# CH32H417 register map
Vendor: WCH Ltd.; File version: 1.3
Registers are 32-bit, read-write, reset 0x0 unless marked. A register's access mark holds for its fields unless they carry their own. Offsets are from the block's base; [hi:lo] are bit positions; {n}, {i} and the like mark numbered series; 'fields as' and 'values as' point back to an identical list.

## CAN1 — Controller area network
Base 0x40006400
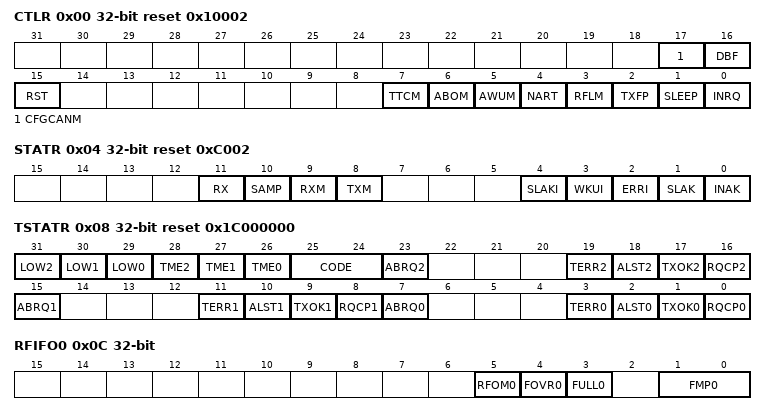
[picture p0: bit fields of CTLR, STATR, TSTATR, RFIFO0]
0x00 CTLR reset 0x10002 — CAN Master control register
  [17] CFGCANM — Configure CAN offline recovery time
  [16] DBF — Debug freeze
  [15] RST — Software master reset
  [7] TTCM — Time triggered communication mode
  [6] ABOM — Automatic bus-off management
  [5] AWUM — Automatic wakeup mode
  [4] NART — No automatic retransmission
  [3] RFLM — Receive FIFO locked mode
  [2] TXFP — Transmit FIFO priority
  [1] SLEEP — Sleep mode request bit
  [0] INRQ — Initialization request
0x04 STATR access per field reset 0xC002 — CAN master status register
  [11] RX ro — Rx signal
  [10] SAMP ro — Last sample point
  [9] RXM ro — Receive mode
  [8] TXM ro — Transmit mode
  [4] SLAKI rw — Sleep acknowledge interrupt
  [3] WKUI rw — Wakeup interrupt
  [2] ERRI rw — Error interrupt
  [1] SLAK ro — Sleep acknowledge
  [0] INAK ro — Initialization acknowledge
0x08 TSTATR access per field reset 0x1C000000 — CAN transmit status register
  [31] LOW2 ro — Lowest priority flag for mailbox2
  [30] LOW1 ro — Lowest priority flag for mailbox1
  [29] LOW0 ro — Lowest priority flag for mailbox0
  [28] TME2 ro — Transmit mailbox 2 empty
  [27] TME1 ro — Transmit mailbox 1 empty
  [26] TME0 ro — Transmit mailbox 0 empty
  [25:24] CODE ro — Mailbox code
  [23] ABRQ2 rw — Abort request for mailbox 2
  [19] TERR2 rw — Transmission error of mailbox 2
  [18] ALST2 rw — Arbitration lost for mailbox 2
  [17] TXOK2 rw — Transmission OK of mailbox 2
  [16] RQCP2 rw — Request completed mailbox2
  [15] ABRQ1 rw — Abort request for mailbox 1
  [11] TERR1 rw — Transmission error of mailbox1
  [10] ALST1 rw — Arbitration lost for mailbox1
  [9] TXOK1 rw — Transmission OK of mailbox1
  [8] RQCP1 rw — Request completed mailbox1
  [7] ABRQ0 rw — Abort request for mailbox0
  [3] TERR0 rw — Transmission error of mailbox0
  [2] ALST0 rw — Arbitration lost for mailbox0
  [1] TXOK0 rw — Transmission OK of mailbox0
  [0] RQCP0 rw — Request completed mailbox0
0x0C RFIFO0 access per field — CAN receive FIFO 0 register
  [5] RFOM0 rw — Release FIFO 0 output mailbox
  [4] FOVR0 rw — FIFO 0 overrun
  [3] FULL0 rw — FIFO 0 full
  [1:0] FMP0 ro — FIFO 0 message pending
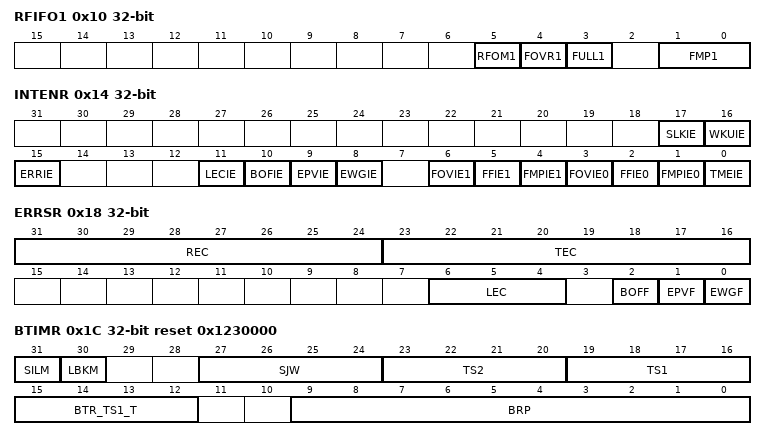
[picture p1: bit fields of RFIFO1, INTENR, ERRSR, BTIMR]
0x10 RFIFO1 access per field — CAN receive FIFO 1 register
  [5] RFOM1 rw — Release FIFO 1 output mailbox
  [4] FOVR1 rw — FIFO 1 overrun
  [3] FULL1 rw — FIFO 1 full
  [1:0] FMP1 ro — FIFO 1 message pending
0x14 INTENR — CAN interrupt enable register
  [17] SLKIE — Sleep interrupt enable
  [16] WKUIE — Wakeup interrupt enable
  [15] ERRIE — Error interrupt enable
  [11] LECIE — Last error code interrupt enable
  [10] BOFIE — Bus-off interrupt enable
  [9] EPVIE — Error passive interrupt enable
  [8] EWGIE — Error warning interrupt enable
  [6] FOVIE1 — FIFO overrun interrupt enable
  [5] FFIE1 — FIFO full interrupt enable
  [4] FMPIE1 — FIFO message pending interrupt enable
  [3] FOVIE0 — FIFO overrun interrupt enable
  [2] FFIE0 — FIFO full interrupt enable
  [1] FMPIE0 — FIFO message pending interrupt enable
  [0] TMEIE — Transmit mailbox empty interrupt enable
0x18 ERRSR access per field — CAN error status register
  [31:24] REC ro — Receive error counter
  [23:16] TEC ro — Least significant byte of the 9-bit transmit error counter
  [6:4] LEC rw — Last error code
  [2] BOFF ro — Bus-off flag
  [1] EPVF ro — Error passive flag
  [0] EWGF ro — Error warning flag
0x1C BTIMR reset 0x1230000 — CAN bit timing register
  [31] SILM — Silent mode (debug)
  [30] LBKM — Loop back mode (debug)
  [27:24] SJW — Resynchronization jump width
  [23:20] TS2 — Time segment 2
  [19:16] TS1 — Time segment 1
  [15:12] BTR_TS1_T — CLAS_LONG_TS1=0;TS1 is TS[3:0](4bit);CLAS_LONG_TS1=1,TS1 is TS[1:0]+BTR_TS1_T[15:12](6bit)
  [9:0] BRP — minimum time unit length setting value
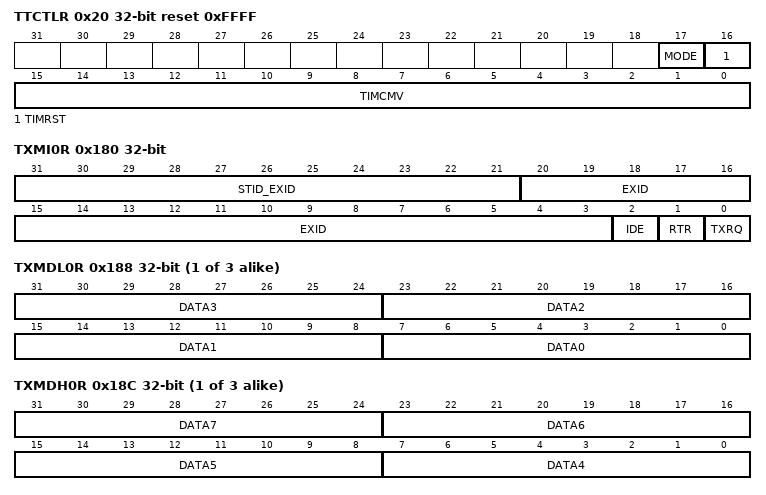
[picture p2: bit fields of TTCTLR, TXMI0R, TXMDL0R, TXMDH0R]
0x20 TTCTLR reset 0xFFFF — CAN time trigger control register
  [17] MODE — Time-triggered mode selection
  [16] TIMRST wo — Internal counter reset control
  [15:0] TIMCMV — Internal counter count end value
0x24 TTCNT — CAN Time Trigger Count Value Register
  [15:0] TIMCNT — time-triggered count value
0x28 TERR_CNT — CAN offline recovery error counter
  [8:0] TX_ERR_CNT — Offline recovery error count values
0x180 TXMI0R — CAN TX mailbox identifier register
  [31:21] STID_EXID — Standard identifier
  [20:3] EXID — extended identifier
  [2] IDE — Identifier extension
  [1] RTR — Remote transmission request
  [0] TXRQ — Transmit mailbox request
0x184 TXMDT0R — CAN mailbox data length control and time stamp register
  [31:16] TIME — Message time stamp
  [15:8] FMI ro — Filter match index
  [8] TGT — Transmit global time
  [3:0] DLC — Data length code
{0x188+0x10*i} TXMDL{i}R (i=0..2) — CAN mailbox data low register
  [8n+7:8n] DATA{n} (n=0..3) — Data byte {n}
{0x18C+0x10*i} TXMDH{i}R (i=0..2) — CAN mailbox data high register
  [8n-25:8n-32] DATA{n} (n=4..7) — Data byte {n}
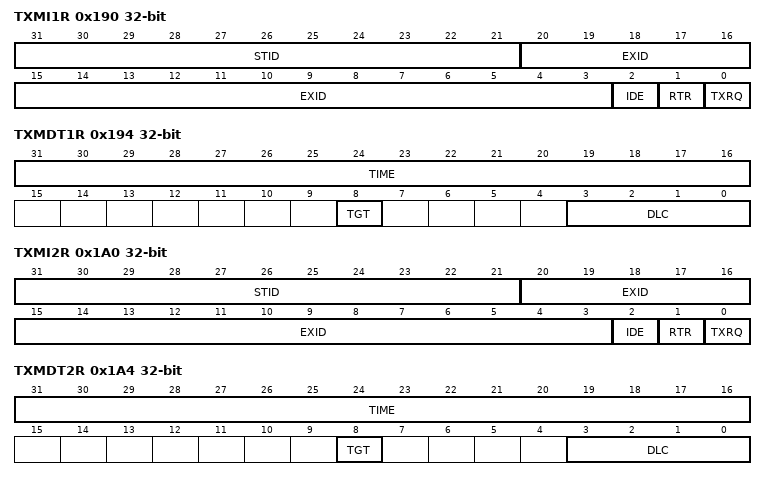
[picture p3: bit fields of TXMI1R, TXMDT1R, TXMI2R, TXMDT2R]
0x190 TXMI1R — CAN TX mailbox identifier register
  [31:21] STID — Standard identifier
  [20:3] EXID — extended identifier
  [2] IDE — Identifier extension
  [1] RTR — Remote transmission request
  [0] TXRQ — Transmit mailbox request
0x194 TXMDT1R — CAN mailbox data length control and time stamp register
  [31:16] TIME — Message time stamp
  [8] TGT — Transmit global time
  [3:0] DLC — Data length code
0x1A0 TXMI2R — CAN TX mailbox identifier register
  fields as TXMI1R
0x1A4 TXMDT2R — CAN mailbox data length control and time stamp register
  fields as TXMDT1R
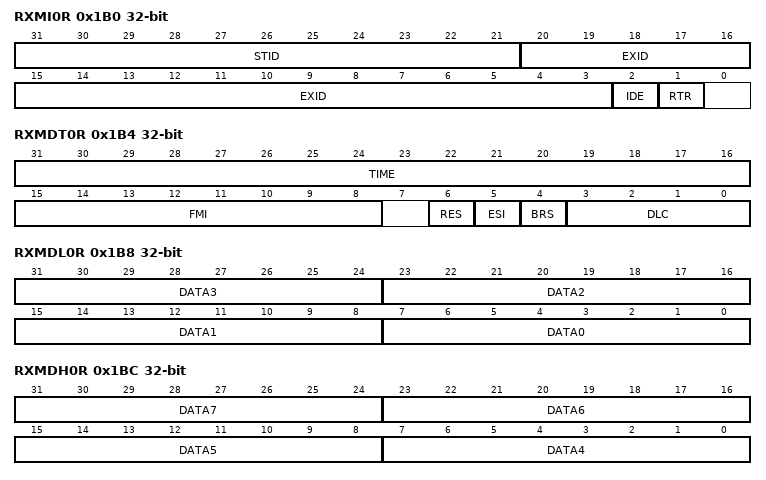
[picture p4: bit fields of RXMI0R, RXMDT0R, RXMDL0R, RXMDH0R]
0x1B0 RXMI0R ro — CAN receive FIFO mailbox identifier register
  [31:21] STID — Standard identifier
  [20:3] EXID — extended identifier
  [2] IDE — Identifier extension
  [1] RTR — Remote transmission request
0x1B4 RXMDT0R ro — CAN receive FIFO mailbox data length control and time stamp register
  [31:16] TIME — Message time stamp
  [15:8] FMI — Filter match index
  [6] RES — RES bit of the received frame
  [5] ESI — ESI bit of the received frame
  [4] BRS — BRS bit of the received frame
  [3:0] DLC — Data length code
0x1B8 RXMDL0R ro — CAN receive FIFO mailbox data low register
  [8n+7:8n] DATA{n} (n=0..3) — Data Byte {n}
0x1BC RXMDH0R ro — CAN receive FIFO mailbox data high register
  [8n-25:8n-32] DATA{n} (n=4..7)
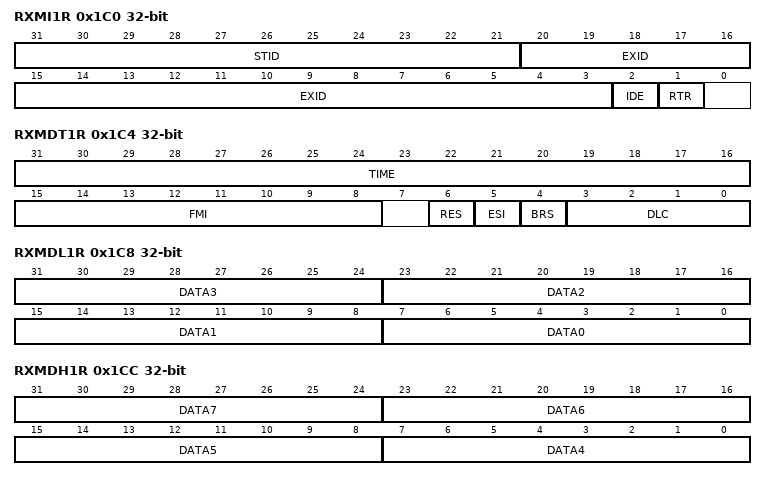
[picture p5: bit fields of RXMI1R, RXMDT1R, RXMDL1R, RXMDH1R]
0x1C0 RXMI1R ro — CAN receive FIFO mailbox identifier register
  fields as RXMI0R
0x1C4 RXMDT1R ro — CAN receive FIFO mailbox data length control and time stamp register
  fields as RXMDT0R
0x1C8 RXMDL1R ro — CAN receive FIFO mailbox data low register
  [8n+7:8n] DATA{n} (n=0..3) — Data Byte {n}
0x1CC RXMDH1R ro — CAN receive FIFO mailbox data high register
  [8n-25:8n-32] DATA{n} (n=4..7)
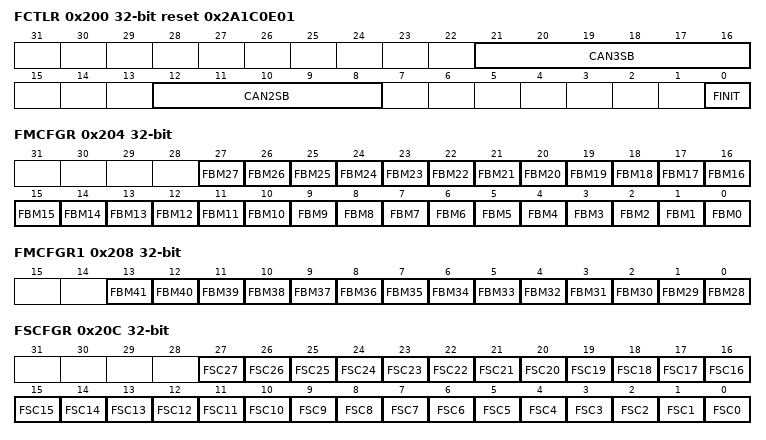
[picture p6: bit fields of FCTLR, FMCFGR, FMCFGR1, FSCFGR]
0x200 FCTLR reset 0x2A1C0E01 — CAN filter master register
  [21:16] CAN3SB — CAN3 start bank
  [12:8] CAN2SB — CAN2 start bank
  [0] FINIT — Filter init mode
0x204 FMCFGR — CAN filter mode register
  [n] FBM{n} (n=0..27) — Filter mode
0x208 FMCFGR1 — CAN filter mode register 1
  [n-28] FBM{n} (n=28..41) — Filter mode
0x20C FSCFGR — CAN filter scale register
  [n] FSC{n} (n=0..27) — Filter scale configuration
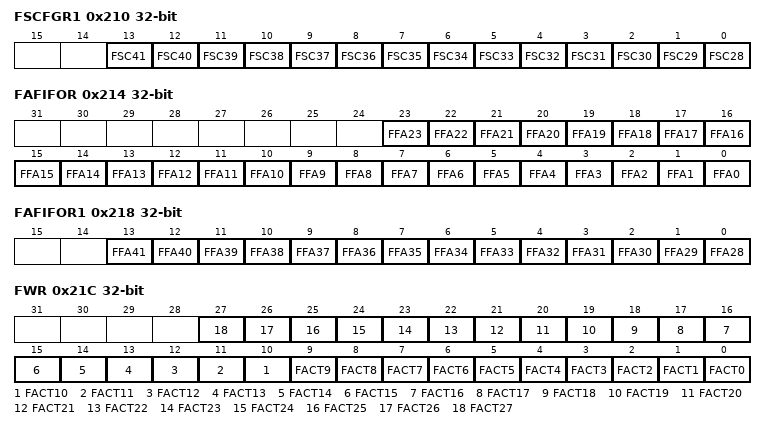
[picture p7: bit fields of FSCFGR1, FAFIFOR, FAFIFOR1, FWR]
0x210 FSCFGR1 — CAN filter scale register 1
  [n-28] FSC{n} (n=28..41) — Filter scale configuration
0x214 FAFIFOR — CAN filter FIFO assignment register
  [n] FFA{n} (n=0..23) — Filter FIFO assignment for filter {n}
0x218 FAFIFOR1 — CAN filter FIFO assignment register 1
  [n-28] FFA{n} (n=28..41) — Filter FIFO assignment for filter {n}
0x21C FWR — CAN filter activation register
  [n] FACT{n} (n=0..27) — Filter active
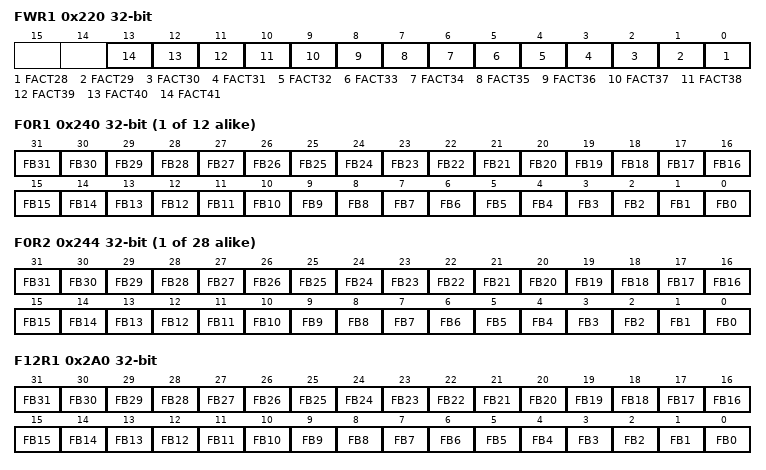
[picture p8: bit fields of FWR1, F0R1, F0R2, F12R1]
0x220 FWR1 — CAN filter activation register 1
  [n-28] FACT{n} (n=28..41) — Filter active
{0x240+8i} F{i}R1 (i=0..11) — Filter bank {i} register 1
  [n] FB{n} (n=0..31) — Filter bits
{0x244+8i} F{i}R2 (i=0..27) — Filter bank {i} register 2
  [n] FB{n} (n=0..31) — Filter bits
0x2A0 F12R1 — Filter bank 4 register 1
  [n] FB{n} (n=0..31) — Filter bits
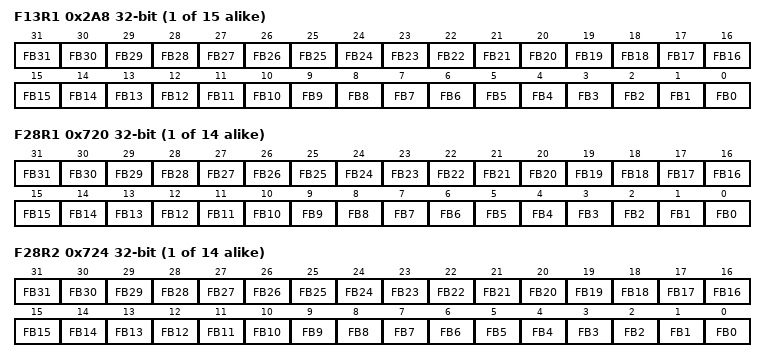
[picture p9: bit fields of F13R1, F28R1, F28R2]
{0x240+8i} F{i}R1 (i=13..27) — Filter bank {i} register 1
  [n] FB{n} (n=0..31) — Filter bits
{0x640+8i} F{i}R1 (i=28..41) — Filter bank {i} register 1
  [n] FB{n} (n=0..31) — Filter bits
{0x644+8i} F{i}R2 (i=28..41) — Filter bank {i} register 2
  [n] FB{n} (n=0..31) — Filter bits

## CAN2
Base 0x40006800
Same registers: CAN3 0x40007800
Registers as CAN1, without FCTLR, FMCFGR, FMCFGR1, FSCFGR, FSCFGR1, FAFIFOR, FAFIFOR1, FWR, FWR1, F{n}R1 (n=0..41), F{n}R2 (n=0..41); these are added or differ:
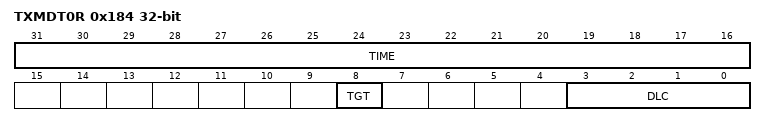
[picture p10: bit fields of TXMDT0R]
0x184 TXMDT0R — CAN mailbox data length control and time stamp register
  [31:16] TIME — Message time stamp
  [8] TGT — Transmit global time
  [3:0] DLC — Data length code
